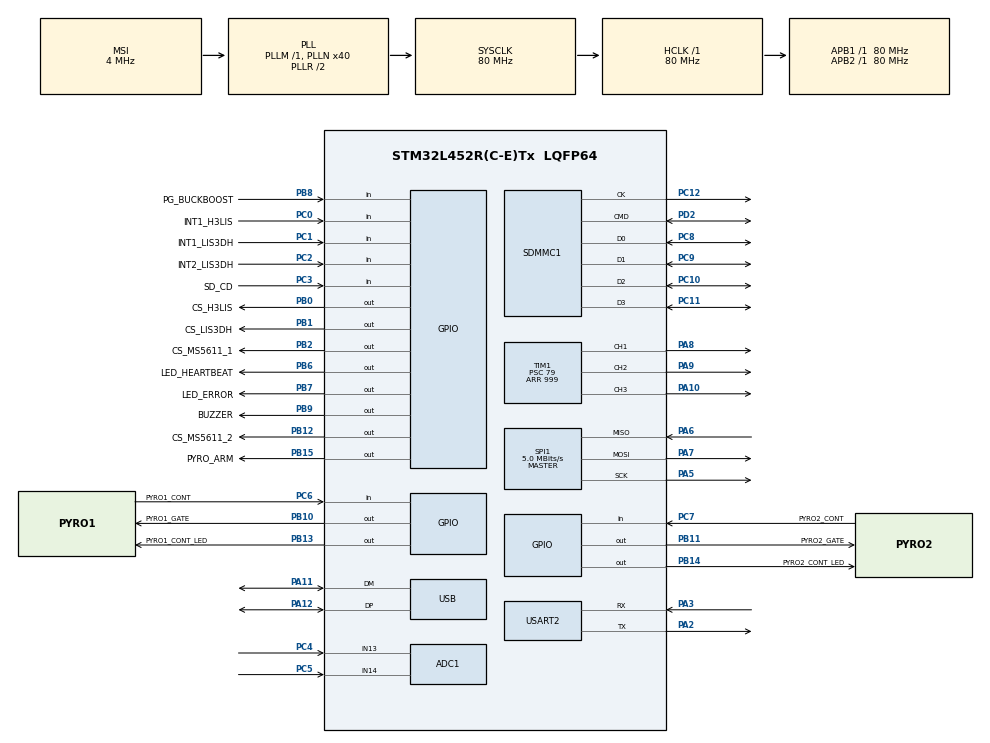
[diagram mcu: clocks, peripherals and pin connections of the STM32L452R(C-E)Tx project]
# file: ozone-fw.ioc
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ADC1.Channel-0\#ChannelRegularConversion=ADC_CHANNEL_13
ADC1.NbrOfConversion=1
ADC1.NbrOfConversionFlag=1
ADC1.OffsetNumber-0\#ChannelRegularConversion=ADC_OFFSET_NONE
ADC1.Rank-0\#ChannelRegularConversion=1
ADC1.SamplingTime-0\#ChannelRegularConversion=ADC_SAMPLETIME_247CYCLES_5
ADC1.master=1
FATFS.BSP.number=1
FATFS._USE_EXPAND=1
FATFS0.BSP.STBoard=false
FATFS0.BSP.api=Unknown
FATFS0.BSP.instance=PC3
FATFS0.BSP.ip=GPIO
FATFS0.BSP.mode=Input
FATFS0.BSP.name=Detect_SDIO
FATFS0.BSP.solution=PC3
Mcu.Family=STM32L4
Mcu.Name=STM32L452R(C-E)Tx
Mcu.Package=LQFP64
NVIC.PriorityGroup=NVIC_PRIORITYGROUP_4
NVIC.USB_IRQn=true\:0\:0\:false\:false\:true\:false\:true\:true
PA10.Signal=S_TIM1_CH3
PA11.Mode=Device
PA11.Signal=USB_DM
PA12.Mode=Device
PA12.Signal=USB_DP
PA13\ (JTMS/SWDIO).Mode=Serial_Wire
PA13\ (JTMS/SWDIO).Signal=SYS_JTMS-SWDIO
PA14\ (JTCK/SWCLK).Mode=Serial_Wire
PA14\ (JTCK/SWCLK).Signal=SYS_JTCK-SWCLK
PA2.Mode=Asynchronous
PA2.Signal=USART2_TX
PA3.Mode=Asynchronous
PA3.Signal=USART2_RX
PA5.Mode=Full_Duplex_Master
PA5.Signal=SPI1_SCK
PA6.Mode=Full_Duplex_Master
PA6.Signal=SPI1_MISO
PA7.Mode=Full_Duplex_Master
PA7.Signal=SPI1_MOSI
PA8.Signal=S_TIM1_CH1
PA9.Signal=S_TIM1_CH2
PB0.GPIO_Label=CS_H3LIS
PB0.PinState=GPIO_PIN_SET
PB0.Signal=GPIO_Output
PB1.GPIO_Label=CS_LIS3DH
PB1.PinState=GPIO_PIN_SET
PB1.Signal=GPIO_Output
PB10.GPIO_Label=PYRO1_GATE
PB10.Signal=GPIO_Output
PB11.GPIO_Label=PYRO2_GATE
PB11.Signal=GPIO_Output
PB12.GPIO_Label=CS_MS5611_2
PB12.PinState=GPIO_PIN_SET
PB12.Signal=GPIO_Output
PB13.GPIO_Label=PYRO1_CONT_LED
PB13.Signal=GPIO_Output
PB14.GPIO_Label=PYRO2_CONT_LED
PB14.Signal=GPIO_Output
PB15.GPIO_Label=PYRO_ARM
PB15.Signal=GPIO_Output
PB2.GPIO_Label=CS_MS5611_1
PB2.PinState=GPIO_PIN_SET
PB2.Signal=GPIO_Output
PB6.GPIO_Label=LED_HEARTBEAT
PB6.Signal=GPIO_Output
PB7.GPIO_Label=LED_ERROR
PB7.Signal=GPIO_Output
PB8.GPIO_Label=PG_BUCKBOOST
PB8.Signal=GPIO_Input
PB9.GPIO_Label=BUZZER
PB9.Signal=GPIO_Output
PC0.GPIO_Label=INT1_H3LIS
PC0.Signal=GPIO_Input
PC1.GPIO_Label=INT1_LIS3DH
PC1.Signal=GPIO_Input
PC10.GPIO_PuPd=GPIO_PULLUP
PC10.Mode=SD_4_bits_Wide_bus
PC10.Signal=SDMMC1_D2
PC11.GPIO_PuPd=GPIO_PULLUP
PC11.Mode=SD_4_bits_Wide_bus
PC11.Signal=SDMMC1_D3
PC12.Mode=SD_4_bits_Wide_bus
PC12.Signal=SDMMC1_CK
PC2.GPIO_Label=INT2_LIS3DH
PC2.Signal=GPIO_Input
PC3.GPIO_Label=SD_CD
PC3.GPIO_PuPd=GPIO_PULLUP
PC3.Signal=GPIO_Input
PC4.Signal=ADCx_IN13
PC5.Signal=ADCx_IN14
PC6.GPIO_Label=PYRO1_CONT
PC6.Signal=GPIO_Input
PC7.GPIO_Label=PYRO2_CONT
PC7.Signal=GPIO_Input
PC8.GPIO_PuPd=GPIO_PULLUP
PC8.Mode=SD_4_bits_Wide_bus
PC8.Signal=SDMMC1_D0
PC9.GPIO_PuPd=GPIO_PULLUP
PC9.Mode=SD_4_bits_Wide_bus
PC9.Signal=SDMMC1_D1
PD2.GPIO_PuPd=GPIO_PULLUP
PD2.Mode=SD_4_bits_Wide_bus
PD2.Signal=SDMMC1_CMD
PH0-OSC_IN\ (PH0).Mode=HSE-External-Oscillator
PH0-OSC_IN\ (PH0).Signal=RCC_OSC_IN
PH1-OSC_OUT\ (PH1).Mode=HSE-External-Oscillator
PH1-OSC_OUT\ (PH1).Signal=RCC_OSC_OUT
ProjectManager.HeapSize=0x400
ProjectManager.StackSize=0x1000
ProjectManager.TargetToolchain=STM32CubeIDE
RCC.ADCFreq_Value=48000000
RCC.AHBFreq_Value=80000000
RCC.APB1Freq_Value=80000000
RCC.APB1TimFreq_Value=80000000
RCC.APB2Freq_Value=80000000
RCC.APB2TimFreq_Value=80000000
RCC.CortexFreq_Value=80000000
RCC.HCLKFreq_Value=80000000
RCC.HSE_VALUE=8000000
RCC.HSI48_VALUE=48000000
RCC.HSI_VALUE=16000000
RCC.LSE_VALUE=32768
RCC.MSI_VALUE=4000000
RCC.PLLN=40
RCC.PLLSAI1N=24
RCC.SYSCLKFreq_VALUE=80000000
RCC.SYSCLKSource=RCC_SYSCLKSOURCE_PLLCLK
RCC.USBFreq_Value=48000000
RCC.VCOOutputFreq_Value=160000000
SH.ADCx_IN13.0=ADC1_IN13,IN13-Single-Ended
SH.ADCx_IN14.0=ADC1_IN14,IN14-Single-Ended
SH.S_TIM1_CH1.0=TIM1_CH1,PWM Generation1 CH1
SH.S_TIM1_CH2.0=TIM1_CH2,PWM Generation2 CH2
SH.S_TIM1_CH3.0=TIM1_CH3,Output Compare3 CH3
SPI1.BaudRatePrescaler=SPI_BAUDRATEPRESCALER_16
SPI1.CLKPhase=SPI_PHASE_2EDGE
SPI1.CLKPolarity=SPI_POLARITY_HIGH
SPI1.CalculateBaudRate=5.0 MBits/s
SPI1.DataSize=SPI_DATASIZE_8BIT
SPI1.Direction=SPI_DIRECTION_2LINES
SPI1.Mode=SPI_MODE_MASTER
SPI1.VirtualType=VM_MASTER
TIM1.Channel-Output\ Compare3\ CH3=TIM_CHANNEL_3
TIM1.Channel-PWM\ Generation1\ CH1=TIM_CHANNEL_1
TIM1.Channel-PWM\ Generation2\ CH2=TIM_CHANNEL_2
TIM1.Period=999
TIM1.Prescaler=79
USART2.VirtualMode-Asynchronous=VM_ASYNC
USB_DEVICE.CLASS_NAME_FS=CDC
USB_DEVICE.VirtualMode=Cdc
USB_DEVICE.VirtualModeFS=Cdc_FS
VP_FATFS_VS_SDIO.Mode=SDIO
VP_TIM6_VS_ClockSourceINT.Mode=Enable_Timer
VP_USB_DEVICE_VS_USB_DEVICE_CDC_FS.Mode=CDC_FS
board=custom

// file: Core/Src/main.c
/* USER CODE BEGIN Header */
/**
  ******************************************************************************
  * @file           : main.c
  * @brief          : Main program body
  ******************************************************************************
  * @attention
  *
  * Copyright (c) 2026 STMicroelectronics.
  * All rights reserved.
  *
  * This software is licensed under terms that can be found in the LICENSE file
  * in the root directory of this software component.
  * If no LICENSE file comes with this software, it is provided AS-IS.
  *
  ******************************************************************************
  */
/* USER CODE END Header */
#include "main.h"
#include "fatfs.h"
#include "usb_device.h"

/* USER CODE BEGIN Includes */
#include "ozone_app.h"
/* USER CODE END Includes */

ADC_HandleTypeDef hadc1;

SD_HandleTypeDef hsd1;

SPI_HandleTypeDef hspi1;

TIM_HandleTypeDef htim1;
TIM_HandleTypeDef htim6;

UART_HandleTypeDef huart2;

void SystemClock_Config(void);
void PeriphCommonClock_Config(void);
static void MX_GPIO_Init(void);
static void MX_ADC1_Init(void);
static void MX_SDMMC1_SD_Init(void);
static void MX_SPI1_Init(void);
static void MX_TIM1_Init(void);
static void MX_TIM6_Init(void);
static void MX_USART2_UART_Init(void);

int main(void)
{

  /* MCU Configuration--------------------------------------------------------*/

  /* Reset of all peripherals, Initializes the Flash interface and the Systick. */
  HAL_Init();

  /* Configure the system clock */
  SystemClock_Config();

  /* Configure the peripherals common clocks */
  PeriphCommonClock_Config();

  /* Initialize all configured peripherals */
  MX_GPIO_Init();
  MX_ADC1_Init();
  MX_SDMMC1_SD_Init();
  MX_SPI1_Init();
  MX_TIM1_Init();
  MX_TIM6_Init();
  MX_USART2_UART_Init();
  MX_FATFS_Init();
  MX_USB_DEVICE_Init();
  /* USER CODE BEGIN 2 */
  ozone_app_init();
  /* USER CODE END 2 */

  /* Infinite loop */
  /* USER CODE BEGIN WHILE */
  while (1)
  {
    ozone_app_run();
    /* USER CODE END WHILE */

  }
}

void SystemClock_Config(void)
{
  RCC_OscInitTypeDef RCC_OscInitStruct = {0};
  RCC_ClkInitTypeDef RCC_ClkInitStruct = {0};

  /** Configure the main internal regulator output voltage
  */
  if (HAL_PWREx_ControlVoltageScaling(PWR_REGULATOR_VOLTAGE_SCALE1) != HAL_OK)
  {
    Error_Handler();
  }

  /** Initializes the RCC Oscillators according to the specified parameters
  * in the RCC_OscInitTypeDef structure.
  */
  RCC_OscInitStruct.OscillatorType = RCC_OSCILLATORTYPE_MSI;
  RCC_OscInitStruct.MSIState = RCC_MSI_ON;
  RCC_OscInitStruct.MSICalibrationValue = 0;
  RCC_OscInitStruct.MSIClockRange = RCC_MSIRANGE_6;
  RCC_OscInitStruct.PLL.PLLState = RCC_PLL_ON;
  RCC_OscInitStruct.PLL.PLLSource = RCC_PLLSOURCE_MSI;
  RCC_OscInitStruct.PLL.PLLM = 1;
  RCC_OscInitStruct.PLL.PLLN = 40;
  RCC_OscInitStruct.PLL.PLLP = RCC_PLLP_DIV7;
  RCC_OscInitStruct.PLL.PLLQ = RCC_PLLQ_DIV2;
  RCC_OscInitStruct.PLL.PLLR = RCC_PLLR_DIV2;
  if (HAL_RCC_OscConfig(&RCC_OscInitStruct) != HAL_OK)
  {
    Error_Handler();
  }

  /** Initializes the CPU, AHB and APB buses clocks
  */
  RCC_ClkInitStruct.ClockType = RCC_CLOCKTYPE_HCLK|RCC_CLOCKTYPE_SYSCLK
                              |RCC_CLOCKTYPE_PCLK1|RCC_CLOCKTYPE_PCLK2;
  RCC_ClkInitStruct.SYSCLKSource = RCC_SYSCLKSOURCE_PLLCLK;
  RCC_ClkInitStruct.AHBCLKDivider = RCC_SYSCLK_DIV1;
  RCC_ClkInitStruct.APB1CLKDivider = RCC_HCLK_DIV1;
  RCC_ClkInitStruct.APB2CLKDivider = RCC_HCLK_DIV1;

  if (HAL_RCC_ClockConfig(&RCC_ClkInitStruct, FLASH_LATENCY_4) != HAL_OK)
  {
    Error_Handler();
  }
}

void PeriphCommonClock_Config(void)
{
  RCC_PeriphCLKInitTypeDef PeriphClkInit = {0};

  /** Initializes the peripherals clock
  */
  PeriphClkInit.PeriphClockSelection = RCC_PERIPHCLK_USB|RCC_PERIPHCLK_SDMMC1
                              |RCC_PERIPHCLK_ADC;
  PeriphClkInit.AdcClockSelection = RCC_ADCCLKSOURCE_PLLSAI1;
  PeriphClkInit.UsbClockSelection = RCC_USBCLKSOURCE_PLLSAI1;
  PeriphClkInit.Sdmmc1ClockSelection = RCC_SDMMC1CLKSOURCE_PLLSAI1;
  PeriphClkInit.PLLSAI1.PLLSAI1Source = RCC_PLLSOURCE_MSI;
  PeriphClkInit.PLLSAI1.PLLSAI1M = 1;
  PeriphClkInit.PLLSAI1.PLLSAI1N = 24;
  PeriphClkInit.PLLSAI1.PLLSAI1P = RCC_PLLP_DIV7;
  PeriphClkInit.PLLSAI1.PLLSAI1Q = RCC_PLLQ_DIV2;
  PeriphClkInit.PLLSAI1.PLLSAI1R = RCC_PLLR_DIV2;
  PeriphClkInit.PLLSAI1.PLLSAI1ClockOut = RCC_PLLSAI1_48M2CLK|RCC_PLLSAI1_ADC1CLK;
  if (HAL_RCCEx_PeriphCLKConfig(&PeriphClkInit) != HAL_OK)
  {
    Error_Handler();
  }
}

static void MX_ADC1_Init(void)
{

  ADC_ChannelConfTypeDef sConfig = {0};

  /** Common config
  */
  hadc1.Instance = ADC1;
  hadc1.Init.ClockPrescaler = ADC_CLOCK_ASYNC_DIV1;
  hadc1.Init.Resolution = ADC_RESOLUTION_12B;
  hadc1.Init.DataAlign = ADC_DATAALIGN_RIGHT;
  hadc1.Init.ScanConvMode = ADC_SCAN_DISABLE;
  hadc1.Init.EOCSelection = ADC_EOC_SINGLE_CONV;
  hadc1.Init.LowPowerAutoWait = DISABLE;
  hadc1.Init.ContinuousConvMode = DISABLE;
  hadc1.Init.NbrOfConversion = 1;
  hadc1.Init.DiscontinuousConvMode = DISABLE;
  hadc1.Init.ExternalTrigConv = ADC_SOFTWARE_START;
  hadc1.Init.ExternalTrigConvEdge = ADC_EXTERNALTRIGCONVEDGE_NONE;
  hadc1.Init.DMAContinuousRequests = DISABLE;
  hadc1.Init.Overrun = ADC_OVR_DATA_PRESERVED;
  hadc1.Init.OversamplingMode = DISABLE;
  if (HAL_ADC_Init(&hadc1) != HAL_OK)
  {
    Error_Handler();
  }

  /** Configure Regular Channel
  */
  sConfig.Channel = ADC_CHANNEL_13;
  sConfig.Rank = ADC_REGULAR_RANK_1;
  sConfig.SamplingTime = ADC_SAMPLETIME_247CYCLES_5;
  sConfig.SingleDiff = ADC_SINGLE_ENDED;
  sConfig.OffsetNumber = ADC_OFFSET_NONE;
  sConfig.Offset = 0;
  if (HAL_ADC_ConfigChannel(&hadc1, &sConfig) != HAL_OK)
  {
    Error_Handler();
  }

}

static void MX_SDMMC1_SD_Init(void)
{

  hsd1.Instance = SDMMC1;
  hsd1.Init.ClockEdge = SDMMC_CLOCK_EDGE_RISING;
  hsd1.Init.ClockBypass = SDMMC_CLOCK_BYPASS_DISABLE;
  hsd1.Init.ClockPowerSave = SDMMC_CLOCK_POWER_SAVE_DISABLE;
  hsd1.Init.BusWide = SDMMC_BUS_WIDE_4B;
  hsd1.Init.HardwareFlowControl = SDMMC_HARDWARE_FLOW_CONTROL_DISABLE;
  hsd1.Init.ClockDiv = 0;

}

static void MX_SPI1_Init(void)
{

  /* SPI1 parameter configuration*/
  hspi1.Instance = SPI1;
  hspi1.Init.Mode = SPI_MODE_MASTER;
  hspi1.Init.Direction = SPI_DIRECTION_2LINES;
  hspi1.Init.DataSize = SPI_DATASIZE_8BIT;
  hspi1.Init.CLKPolarity = SPI_POLARITY_HIGH;
  hspi1.Init.CLKPhase = SPI_PHASE_2EDGE;
  hspi1.Init.NSS = SPI_NSS_SOFT;
  hspi1.Init.BaudRatePrescaler = SPI_BAUDRATEPRESCALER_16;
  hspi1.Init.FirstBit = SPI_FIRSTBIT_MSB;
  hspi1.Init.TIMode = SPI_TIMODE_DISABLE;
  hspi1.Init.CRCCalculation = SPI_CRCCALCULATION_DISABLE;
  hspi1.Init.CRCPolynomial = 7;
  hspi1.Init.CRCLength = SPI_CRC_LENGTH_DATASIZE;
  hspi1.Init.NSSPMode = SPI_NSS_PULSE_DISABLE;
  if (HAL_SPI_Init(&hspi1) != HAL_OK)
  {
    Error_Handler();
  }

}

static void MX_TIM1_Init(void)
{

  TIM_MasterConfigTypeDef sMasterConfig = {0};
  TIM_OC_InitTypeDef sConfigOC = {0};
  TIM_BreakDeadTimeConfigTypeDef sBreakDeadTimeConfig = {0};

  htim1.Instance = TIM1;
  htim1.Init.Prescaler = 79;
  htim1.Init.CounterMode = TIM_COUNTERMODE_UP;
  htim1.Init.Period = 999;
  htim1.Init.ClockDivision = TIM_CLOCKDIVISION_DIV1;
  htim1.Init.RepetitionCounter = 0;
  htim1.Init.AutoReloadPreload = TIM_AUTORELOAD_PRELOAD_DISABLE;
  if (HAL_TIM_PWM_Init(&htim1) != HAL_OK)
  {
    Error_Handler();
  }
  if (HAL_TIM_OC_Init(&htim1) != HAL_OK)
  {
    Error_Handler();
  }
  sMasterConfig.MasterOutputTrigger = TIM_TRGO_RESET;
  sMasterConfig.MasterOutputTrigger2 = TIM_TRGO2_RESET;
  sMasterConfig.MasterSlaveMode = TIM_MASTERSLAVEMODE_DISABLE;
  if (HAL_TIMEx_MasterConfigSynchronization(&htim1, &sMasterConfig) != HAL_OK)
  {
    Error_Handler();
  }
  sConfigOC.OCMode = TIM_OCMODE_PWM1;
  sConfigOC.Pulse = 0;
  sConfigOC.OCPolarity = TIM_OCPOLARITY_HIGH;
  sConfigOC.OCNPolarity = TIM_OCNPOLARITY_HIGH;
  sConfigOC.OCFastMode = TIM_OCFAST_DISABLE;
  sConfigOC.OCIdleState = TIM_OCIDLESTATE_RESET;
  sConfigOC.OCNIdleState = TIM_OCNIDLESTATE_RESET;
  if (HAL_TIM_PWM_ConfigChannel(&htim1, &sConfigOC, TIM_CHANNEL_1) != HAL_OK)
  {
    Error_Handler();
  }
  if (HAL_TIM_PWM_ConfigChannel(&htim1, &sConfigOC, TIM_CHANNEL_2) != HAL_OK)
  {
    Error_Handler();
  }
  sConfigOC.OCMode = TIM_OCMODE_TIMING;
  if (HAL_TIM_OC_ConfigChannel(&htim1, &sConfigOC, TIM_CHANNEL_3) != HAL_OK)
  {
    Error_Handler();
  }
  sBreakDeadTimeConfig.OffStateRunMode = TIM_OSSR_DISABLE;
  sBreakDeadTimeConfig.OffStateIDLEMode = TIM_OSSI_DISABLE;
  sBreakDeadTimeConfig.LockLevel = TIM_LOCKLEVEL_OFF;
  sBreakDeadTimeConfig.DeadTime = 0;
  sBreakDeadTimeConfig.BreakState = TIM_BREAK_DISABLE;
  sBreakDeadTimeConfig.BreakPolarity = TIM_BREAKPOLARITY_HIGH;
  sBreakDeadTimeConfig.BreakFilter = 0;
  sBreakDeadTimeConfig.Break2State = TIM_BREAK2_DISABLE;
  sBreakDeadTimeConfig.Break2Polarity = TIM_BREAK2POLARITY_HIGH;
  sBreakDeadTimeConfig.Break2Filter = 0;
  sBreakDeadTimeConfig.AutomaticOutput = TIM_AUTOMATICOUTPUT_DISABLE;
  if (HAL_TIMEx_ConfigBreakDeadTime(&htim1, &sBreakDeadTimeConfig) != HAL_OK)
  {
    Error_Handler();
  }
  HAL_TIM_MspPostInit(&htim1);

}

static void MX_TIM6_Init(void)
{

  TIM_MasterConfigTypeDef sMasterConfig = {0};

  htim6.Instance = TIM6;
  htim6.Init.Prescaler = 0;
  htim6.Init.CounterMode = TIM_COUNTERMODE_UP;
  htim6.Init.Period = 65535;
  htim6.Init.AutoReloadPreload = TIM_AUTORELOAD_PRELOAD_DISABLE;
  if (HAL_TIM_Base_Init(&htim6) != HAL_OK)
  {
    Error_Handler();
  }
  sMasterConfig.MasterOutputTrigger = TIM_TRGO_RESET;
  sMasterConfig.MasterSlaveMode = TIM_MASTERSLAVEMODE_DISABLE;
  if (HAL_TIMEx_MasterConfigSynchronization(&htim6, &sMasterConfig) != HAL_OK)
  {
    Error_Handler();
  }

}

static void MX_USART2_UART_Init(void)
{

  huart2.Instance = USART2;
  huart2.Init.BaudRate = 115200;
  huart2.Init.WordLength = UART_WORDLENGTH_8B;
  huart2.Init.StopBits = UART_STOPBITS_1;
  huart2.Init.Parity = UART_PARITY_NONE;
  huart2.Init.Mode = UART_MODE_TX_RX;
  huart2.Init.HwFlowCtl = UART_HWCONTROL_NONE;
  huart2.Init.OverSampling = UART_OVERSAMPLING_16;
  huart2.Init.OneBitSampling = UART_ONE_BIT_SAMPLE_DISABLE;
  huart2.AdvancedInit.AdvFeatureInit = UART_ADVFEATURE_NO_INIT;
  if (HAL_UART_Init(&huart2) != HAL_OK)
  {
    Error_Handler();
  }

}

static void MX_GPIO_Init(void)
{
  GPIO_InitTypeDef GPIO_InitStruct = {0};

  /* GPIO Ports Clock Enable */
  __HAL_RCC_GPIOH_CLK_ENABLE();
  __HAL_RCC_GPIOC_CLK_ENABLE();
  __HAL_RCC_GPIOA_CLK_ENABLE();
  __HAL_RCC_GPIOB_CLK_ENABLE();
  __HAL_RCC_GPIOD_CLK_ENABLE();

  /*Configure GPIO pin Output Level */
  HAL_GPIO_WritePin(GPIOB, CS_H3LIS_Pin|CS_LIS3DH_Pin|CS_MS5611_1_Pin|CS_MS5611_2_Pin, GPIO_PIN_SET);

  /*Configure GPIO pin Output Level */
  HAL_GPIO_WritePin(GPIOB, PYRO1_GATE_Pin|PYRO2_GATE_Pin|PYRO1_CONT_LED_Pin|PYRO2_CONT_LED_Pin
                          |PYRO_ARM_Pin|LED_HEARTBEAT_Pin|LED_ERROR_Pin|BUZZER_Pin, GPIO_PIN_RESET);

  /*Configure GPIO pins : INT1_H3LIS_Pin INT1_LIS3DH_Pin INT2_LIS3DH_Pin PYRO1_CONT_Pin
                           PYRO2_CONT_Pin */
  GPIO_InitStruct.Pin = INT1_H3LIS_Pin|INT1_LIS3DH_Pin|INT2_LIS3DH_Pin|PYRO1_CONT_Pin
                          |PYRO2_CONT_Pin;
  GPIO_InitStruct.Mode = GPIO_MODE_INPUT;
  GPIO_InitStruct.Pull = GPIO_NOPULL;
  HAL_GPIO_Init(GPIOC, &GPIO_InitStruct);

  /*Configure GPIO pin : SD_CD_Pin */
  GPIO_InitStruct.Pin = SD_CD_Pin;
  GPIO_InitStruct.Mode = GPIO_MODE_INPUT;
  GPIO_InitStruct.Pull = GPIO_PULLUP;
  HAL_GPIO_Init(SD_CD_GPIO_Port, &GPIO_InitStruct);

  /*Configure GPIO pins : CS_H3LIS_Pin CS_LIS3DH_Pin CS_MS5611_1_Pin PYRO1_GATE_Pin
                           PYRO2_GATE_Pin CS_MS5611_2_Pin PYRO1_CONT_LED_Pin PYRO2_CONT_LED_Pin
                           PYRO_ARM_Pin LED_HEARTBEAT_Pin LED_ERROR_Pin BUZZER_Pin */
  GPIO_InitStruct.Pin = CS_H3LIS_Pin|CS_LIS3DH_Pin|CS_MS5611_1_Pin|PYRO1_GATE_Pin
                          |PYRO2_GATE_Pin|CS_MS5611_2_Pin|PYRO1_CONT_LED_Pin|PYRO2_CONT_LED_Pin
                          |PYRO_ARM_Pin|LED_HEARTBEAT_Pin|LED_ERROR_Pin|BUZZER_Pin;
  GPIO_InitStruct.Mode = GPIO_MODE_OUTPUT_PP;
  GPIO_InitStruct.Pull = GPIO_NOPULL;
  GPIO_InitStruct.Speed = GPIO_SPEED_FREQ_LOW;
  HAL_GPIO_Init(GPIOB, &GPIO_InitStruct);

  /*Configure GPIO pin : PG_BUCKBOOST_Pin */
  GPIO_InitStruct.Pin = PG_BUCKBOOST_Pin;
  GPIO_InitStruct.Mode = GPIO_MODE_INPUT;
  GPIO_InitStruct.Pull = GPIO_NOPULL;
  HAL_GPIO_Init(PG_BUCKBOOST_GPIO_Port, &GPIO_InitStruct);

}

void Error_Handler(void)
{
  __disable_irq();
  while (1)
  {
  }
}
